# c71_UMC register map
Vendor: Texas Instruments
Peripheral module from a debugger description file (folder C71).
Registers are 64-bit, access per field, reset values left out (the file's numbers can be read two ways) unless marked. A register's access mark holds for its fields unless they carry their own. Offsets are as the file gives them; lines under a group give offsets from that group; [hi:lo] are bit positions; {n}, {i} and the like mark numbered series; 'fields as' and 'values as' point back to an identical list; <NAME> marks a mode.

## UMC — L2 Unified Memory Controller
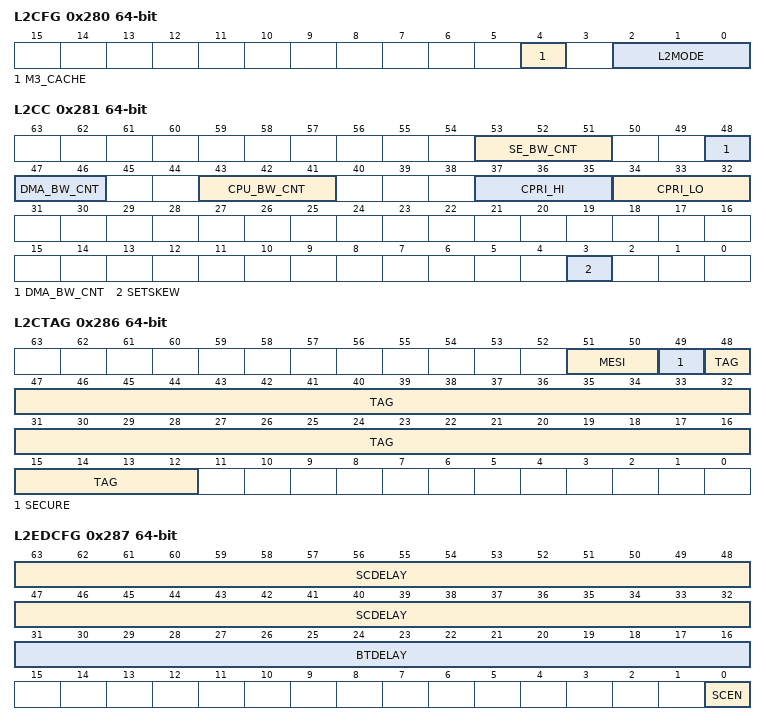
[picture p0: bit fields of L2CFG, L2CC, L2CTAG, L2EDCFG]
0x280 L2CFG — L2 Cache Configuration Register
  [4] M3_CACHE rw — Enable caching of M3 SRAM via ccinner
  [2:0] L2MODE rw — Controls the L2 Cache Size Mode
0x281 L2CC — L2 Cache Control Register
  [53:51] SE_BW_CNT rw — SE0 SE1 relative bandwidth mgmt counter
  [48:46] DMA_BW_CNT rw — DMA bandwidth mgmt counter
  [43:41] CPU_BW_CNT rw — CPU bandwidth mgmt counter
  [37:35] CPRI_HI rw — Elevated priority for mastered commands
  [34:32] CPRI_LO rw — Default priority for mastered commands
  [3] SETSKEW rw — Set/Bank skewing enable
0x282 L2WB — L2 Global Writeback Register
  [0] WB rw — Controls the Global Writeback of L2 Cache
0x283 L2WBINV — L2 Global Writeback Invalidate Register
  [0] WBINV rw — Writeback and invalidate all lines L2 Cache
0x284 L2INV — L2 Invalidate Register
  [0] INV rw — Controls the Global Invalidation of L2 Cache
0x286 L2CTAG ro — L2 Cache tag View\[Access Permissions: Non-Secure Debug=R, Secure Debug=R\]
  [51:50] MESI — MESI Bits includes valid and dirty bits
  [49] SECURE — Secure bit
  [48:12] TAG — L2 Tag
0x287 L2EDCFG — L2 EDC Configuration Control
  [63:32] SCDELAY rw — Delay between full scrub cycles
  [31:16] BTDELAY rw — Delay between scrub bursts
  [0] SCEN rw — Enable L2 Scrubbing
0x291 L2ADDREEA ro — L2 Addressing Error Event Address
  [43:0] EADDR — Transaction address for which error was detected
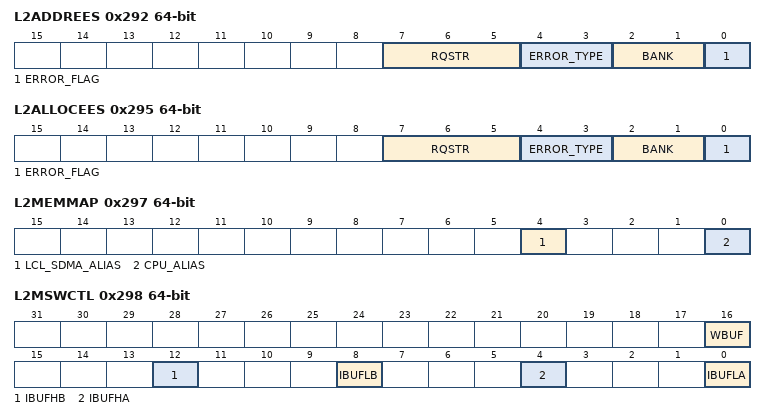
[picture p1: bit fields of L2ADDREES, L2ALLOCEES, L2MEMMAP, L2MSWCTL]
0x292 L2ADDREES ro — L2 Addressing Error Event Status
  [7:5] RQSTR — Requestor of the transaction for which error was detected
  [4:3] ERROR_TYPE — Type of Error
  [2:1] BANK — Bank in which error was detected [0,1,2,3]
  [0] ERROR_FLAG — Indicates that an error has occurred and has not been cleared yet. Clear occurs on a write to L2ADDREER
0x293 L2ADDREER — L2 Addressing Error Event Reset
  [0] ERROR_RESET wo — Clear the error flag
0x294 L2ALLOCEEA ro — L2 CMD Error Event Address
  [43:0] EADDR — Transaction address for which error was detected
0x295 L2ALLOCEES ro — L2 CMD Error Event Status
  fields as L2ADDREES
0x296 L2ALLOCEER — L2 CMD Error Event Reset
  [0] ERROR_RESET wo — Clear the error flag
0x297 L2MEMMAP — L2 Memory Map Control
  [4] LCL_SDMA_ALIAS rw — Local SDMA View - Full Memory Map or Aliased
  [0] CPU_ALIAS rw — CPU View - Full Memory Map or Aliased
0x298 L2MSWCTL — L2 Memory Switch Control
  [16] WBUF rw — WBUF Buffer Ownership
  [12] IBUFHB rw — IBUFHB Buffer Ownership
  [8] IBUFLB rw — IBUFLB Buffer Ownership
  [4] IBUFHA rw — IBUFHA Buffer Ownership
  [0] IBUFLA rw — IBUFLA Buffer Ownership
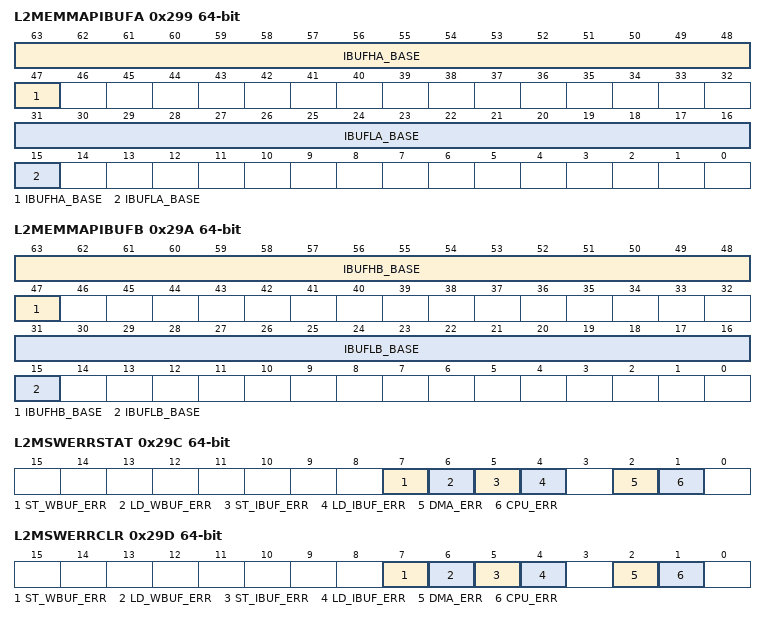
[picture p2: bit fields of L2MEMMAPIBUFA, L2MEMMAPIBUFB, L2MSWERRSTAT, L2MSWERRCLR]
0x299 L2MEMMAPIBUFA — L2 IBUFA Memory Base Control
  [63:47] IBUFHA_BASE rw — IBUFHA Base Address
  [31:15] IBUFLA_BASE rw — IBUFLA Base Address
0x29A L2MEMMAPIBUFB — L2 IBUFB Memory Base Address
  [63:47] IBUFHB_BASE rw — IBUFHB Base Address
  [31:15] IBUFLB_BASE rw — IBUFLB Base Address
0x29B L2MEMMAPWBUF — L2 WBUF Memory Base Address
  [31:15] WBUF_BASE rw — WBUF Base Address
0x29C L2MSWERRSTAT ro — L2 Memory Switch Error Status
  [7] ST_WBUF_ERR — Store to WBUF is outside address range
  [6] LD_WBUF_ERR — Load to WBUF is outside address range
  [5] ST_IBUF_ERR — Store to IBUF is outside address range
  [4] LD_IBUF_ERR — Load to IBUF is outside address range
  [2] DMA_ERR — DMA initiated buffer ownership error
  [1] CPU_ERR — CPU initiated buffer ownership error
0x29D L2MSWERRCLR — L2 Memory Switch Error Clear
  [7] ST_WBUF_ERR wo — Clear ST_WBUF_ERR
  [6] LD_WBUF_ERR wo — Clear LD_WBUF_ERR
  [5] ST_IBUF_ERR wo — Clear ST_IBUF_ERR
  [4] LD_IBUF_ERR wo — Clear LD_IBUF_ERR
  [2] DMA_ERR wo — Clear DMA_ERR
  [1] CPU_ERR wo — Clear CPU_ERR
0x29E L2MSWERRADDR ro — L2 Memory Switch Error Address
  [43:0] ADDR — Error address
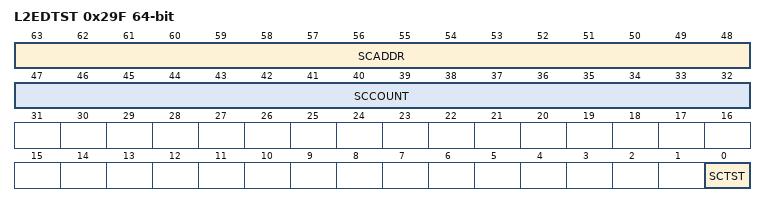
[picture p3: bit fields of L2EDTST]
0x29F L2EDTST — L2 EDC Test Control
  [63:48] SCADDR rw — Starting RAM physical address for test
  [47:32] SCCOUNT rw — Number of scrubs in test
  [0] SCTST rw — Enable L2 scrub test mode
